# COMPUTE_CLUSTER0_A72SS0_CORE0_ECC_AGGR register map
Vendor: Texas Instruments
Peripheral module from a debugger description file (folder J7VCL).
Registers are 32-bit, access not given, reset 0x0 unless marked. A register's access mark holds for its fields unless they carry their own. Offsets are as the file gives them; lines under a group give offsets from that group; [hi:lo] are bit positions; {n}, {i} and the like mark numbered series; 'fields as' and 'values as' point back to an identical list; <NAME> marks a mode.

## COMPUTE_CLUSTER0_A72SS0_CORE0_ECC_AGGR
0x00 A72SS_CORE0_ECC_REV ro reset 0x66A0EA00 — IP revision register.
  [31:0] REV — TI internal data. Identifies revision of peripheral.
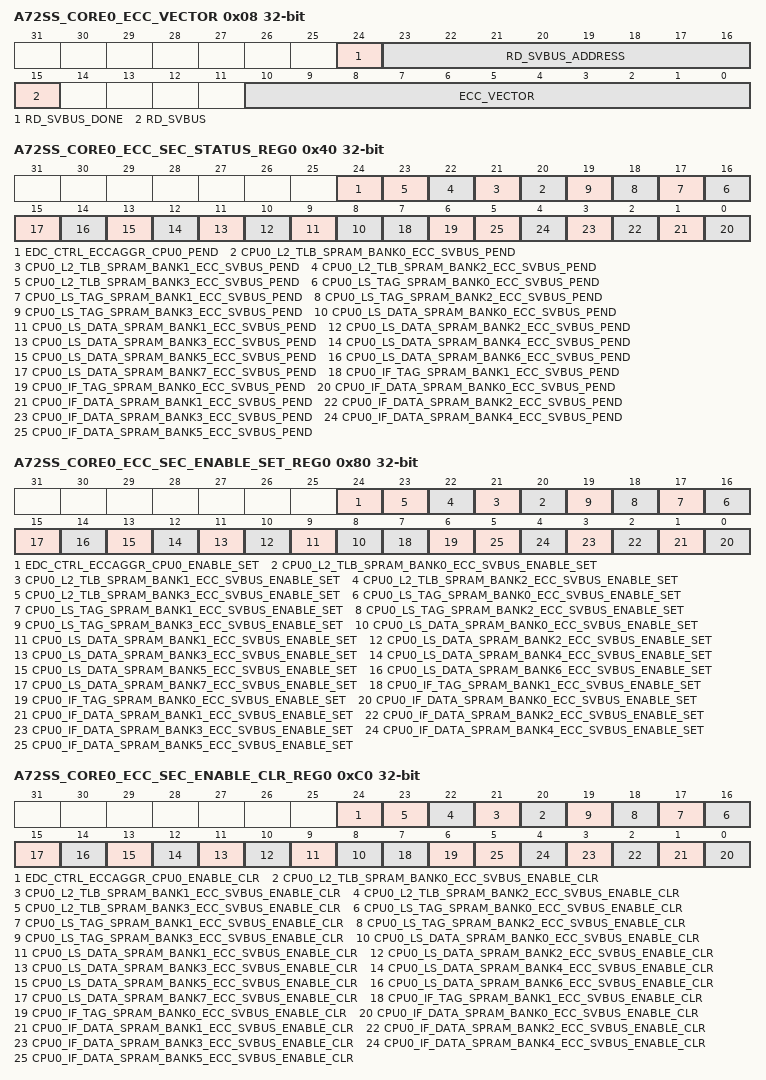
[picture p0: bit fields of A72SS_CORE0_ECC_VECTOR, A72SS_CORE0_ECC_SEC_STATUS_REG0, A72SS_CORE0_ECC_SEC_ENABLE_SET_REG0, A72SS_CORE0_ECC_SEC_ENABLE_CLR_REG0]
0x08 A72SS_CORE0_ECC_VECTOR — ECC vector register.
  [24] RD_SVBUS_DONE — Status to indicate if read on serial VBUS is complete, write of any value will clear this bit. (access RW1C)
  [23:16] RD_SVBUS_ADDRESS rw — Read address
  [15] RD_SVBUS — Write 1 to trigger a read on the serial VBUS (access RW1S)
  [10:0] ECC_VECTOR rw — Value written to select the corresponding ECC RAM for control or status
0x0C A72SS_CORE0_ECC_STAT ro reset 0x19 — Misc status register.
  [10:0] NUM_RAMS — Indicates the number of RAMs serviced by the ECC aggregator
0x3C A72SS_CORE0_ECC_SEC_EOI_REG — SEC EOI register. The EOI register is used to re-trigger the pulse interrupt signal to ensure that any nested interrupt events are serviced. The software interrupt handler must write to the EOI register at the end of the current interrupt processing routine, so that new events can re-trigger the pulse interrupt signal again. For level interrupt signals the EOI register is not functional and must not be used.
  [0] EOI_WR — EOI value (access RW1S)
0x40 A72SS_CORE0_ECC_SEC_STATUS_REG0 — SEC interrupt status register 0.
  [24] EDC_CTRL_ECCAGGR_CPU0_PEND — Interrupt pending status for edc_ctrl_eccaggr_cpu0_pend (access RW1S)
  [n+20] CPU0_L2_TLB_SPRAM_BANK{n}_ECC_SVBUS_PEND (n=0..3) — Interrupt pending status for cpu0_l2_tlb_spram_bank{n}_ecc_svbus_pend (access RW1S)
  [n+16] CPU0_LS_TAG_SPRAM_BANK{n}_ECC_SVBUS_PEND (n=0..3) — Interrupt pending status for cpu0_ls_tag_spram_bank{n}_ecc_svbus_pend (access RW1S)
  [n+8] CPU0_LS_DATA_SPRAM_BANK{n}_ECC_SVBUS_PEND (n=0..7) — Interrupt pending status for cpu0_ls_data_spram_bank{n}_ecc_svbus_pend (access RW1S)
  [7] CPU0_IF_TAG_SPRAM_BANK1_ECC_SVBUS_PEND — Interrupt pending status for cpu0_if_tag_spram_bank1_ecc_svbus_pend (access RW1S)
  [6] CPU0_IF_TAG_SPRAM_BANK0_ECC_SVBUS_PEND — Interrupt pending status for cpu0_if_tag_spram_bank0_ecc_svbus_pend (access RW1S)
  [n] CPU0_IF_DATA_SPRAM_BANK{n}_ECC_SVBUS_PEND (n=0..5) — Interrupt pending status for cpu0_if_data_spram_bank{n}_ecc_svbus_pend (access RW1S)
0x80 A72SS_CORE0_ECC_SEC_ENABLE_SET_REG0 — SEC interrupt enable set register 0.
  [24] EDC_CTRL_ECCAGGR_CPU0_ENABLE_SET — Interrupt enable set for edc_ctrl_eccaggr_cpu0_pend (access RW1S)
  [n+20] CPU0_L2_TLB_SPRAM_BANK{n}_ECC_SVBUS_ENABLE_SET (n=0..3) — Interrupt enable set for cpu0_l2_tlb_spram_bank{n}_ecc_svbus_pend (access RW1S)
  [n+16] CPU0_LS_TAG_SPRAM_BANK{n}_ECC_SVBUS_ENABLE_SET (n=0..3) — Interrupt enable set for cpu0_ls_tag_spram_bank{n}_ecc_svbus_pend (access RW1S)
  [n+8] CPU0_LS_DATA_SPRAM_BANK{n}_ECC_SVBUS_ENABLE_SET (n=0..7) — Interrupt enable set for cpu0_ls_data_spram_bank{n}_ecc_svbus_pend (access RW1S)
  [7] CPU0_IF_TAG_SPRAM_BANK1_ECC_SVBUS_ENABLE_SET — Interrupt enable set for cpu0_if_tag_spram_bank1_ecc_svbus_pend (access RW1S)
  [6] CPU0_IF_TAG_SPRAM_BANK0_ECC_SVBUS_ENABLE_SET — Interrupt enable set for cpu0_if_tag_spram_bank0_ecc_svbus_pend (access RW1S)
  [n] CPU0_IF_DATA_SPRAM_BANK{n}_ECC_SVBUS_ENABLE_SET (n=0..5) — Interrupt enable set for cpu0_if_data_spram_bank{n}_ecc_svbus_pend (access RW1S)
0xC0 A72SS_CORE0_ECC_SEC_ENABLE_CLR_REG0 — SEC interrupt enable clear register 0.
  [24] EDC_CTRL_ECCAGGR_CPU0_ENABLE_CLR — Interrupt enable clear for edc_ctrl_eccaggr_cpu0_pend (access RW1C)
  [n+20] CPU0_L2_TLB_SPRAM_BANK{n}_ECC_SVBUS_ENABLE_CLR (n=0..3) — Interrupt enable clear for cpu0_l2_tlb_spram_bank{n}_ecc_svbus_pend (access RW1C)
  [n+16] CPU0_LS_TAG_SPRAM_BANK{n}_ECC_SVBUS_ENABLE_CLR (n=0..3) — Interrupt enable clear for cpu0_ls_tag_spram_bank{n}_ecc_svbus_pend (access RW1C)
  [n+8] CPU0_LS_DATA_SPRAM_BANK{n}_ECC_SVBUS_ENABLE_CLR (n=0..7) — Interrupt enable clear for cpu0_ls_data_spram_bank{n}_ecc_svbus_pend (access RW1C)
  [7] CPU0_IF_TAG_SPRAM_BANK1_ECC_SVBUS_ENABLE_CLR — Interrupt enable clear for cpu0_if_tag_spram_bank1_ecc_svbus_pend (access RW1C)
  [6] CPU0_IF_TAG_SPRAM_BANK0_ECC_SVBUS_ENABLE_CLR — Interrupt enable clear for cpu0_if_tag_spram_bank0_ecc_svbus_pend (access RW1C)
  [n] CPU0_IF_DATA_SPRAM_BANK{n}_ECC_SVBUS_ENABLE_CLR (n=0..5) — Interrupt enable clear for cpu0_if_data_spram_bank{n}_ecc_svbus_pend (access RW1C)
0x13C A72SS_CORE0_ECC_DED_EOI_REG — DED EOI register. The EOI register is used to re-trigger the pulse interrupt signal to ensure that any nested interrupt events are serviced. The software interrupt handler must write to the EOI register at the end of the current interrupt processing routine, so that new events can re-trigger the pulse interrupt signal again. For level interrupt signals the EOI register is not functional and must not be used.
  [0] EOI_WR — EOI value (access RW1S)
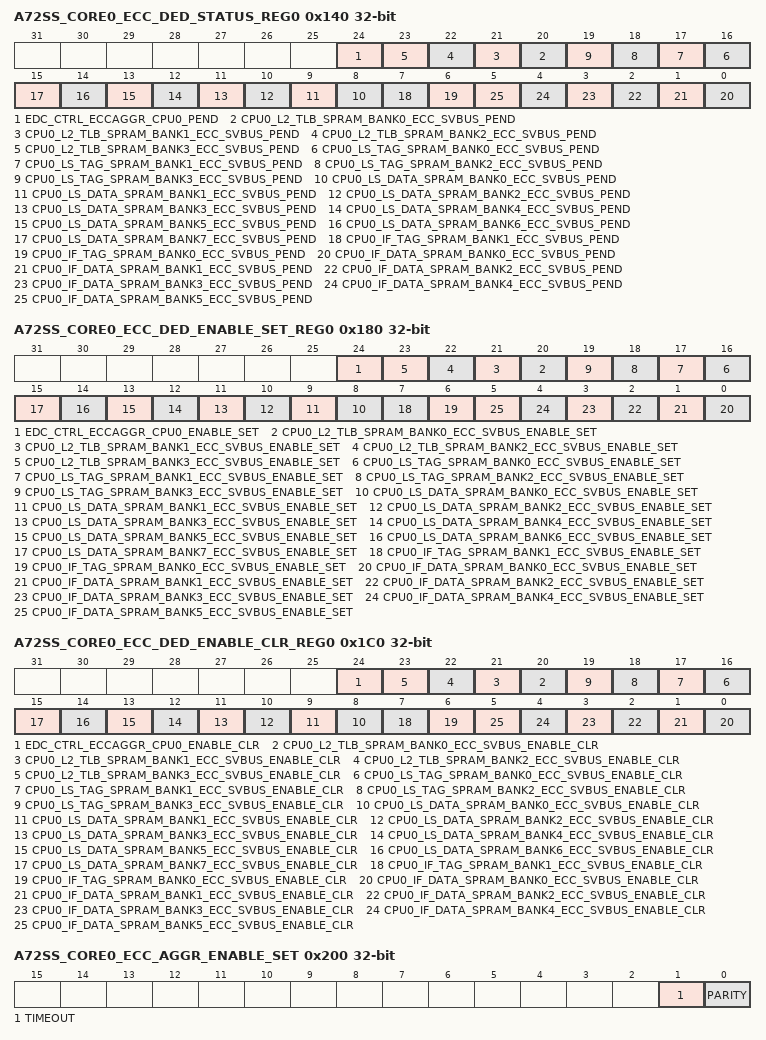
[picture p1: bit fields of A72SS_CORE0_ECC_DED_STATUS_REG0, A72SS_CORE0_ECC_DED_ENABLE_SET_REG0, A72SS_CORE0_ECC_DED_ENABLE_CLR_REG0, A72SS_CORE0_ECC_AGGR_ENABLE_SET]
0x140 A72SS_CORE0_ECC_DED_STATUS_REG0 — DED interrupt status register 0.
  fields as A72SS_CORE0_ECC_SEC_STATUS_REG0
0x180 A72SS_CORE0_ECC_DED_ENABLE_SET_REG0 — DED interrupt enable set register 0.
  fields as A72SS_CORE0_ECC_SEC_ENABLE_SET_REG0
0x1C0 A72SS_CORE0_ECC_DED_ENABLE_CLR_REG0 — DED interrupt enable clear register 0.
  fields as A72SS_CORE0_ECC_SEC_ENABLE_CLR_REG0
0x200 A72SS_CORE0_ECC_AGGR_ENABLE_SET — AGGR interrupt enable set register.
  [1] TIMEOUT — Interrupt enable set for svbus timeout errors (access RW1S)
  [0] PARITY — Interrupt enable set for parity errors (access RW1S)
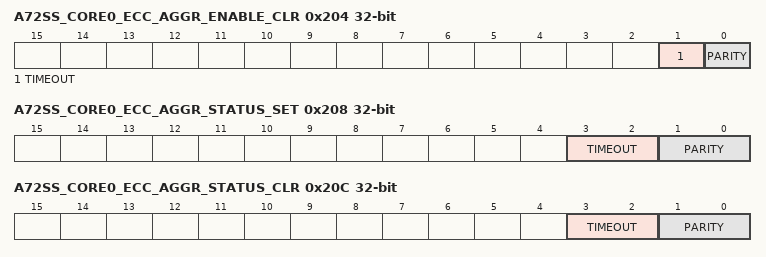
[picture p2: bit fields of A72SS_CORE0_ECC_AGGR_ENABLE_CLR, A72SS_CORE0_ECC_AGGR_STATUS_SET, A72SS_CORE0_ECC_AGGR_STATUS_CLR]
0x204 A72SS_CORE0_ECC_AGGR_ENABLE_CLR — AGGR interrupt enable clear register.
  [1] TIMEOUT — Interrupt enable clear for svbus timeout errors (access RW1C)
  [0] PARITY — Interrupt enable clear for parity errors (access RW1C)
0x208 A72SS_CORE0_ECC_AGGR_STATUS_SET — AGGR interrupt status set register.
  [3:2] TIMEOUT — Interrupt status set for svbus timeout errors (access RWincr)
  [1:0] PARITY — Interrupt status set for parity errors (access RWincr)
0x20C A72SS_CORE0_ECC_AGGR_STATUS_CLR — AGGR interrupt status clear register.
  [3:2] TIMEOUT — Interrupt status clear for svbus timeout errors (access RWdecr)
  [1:0] PARITY — Interrupt status clear for parity errors (access RWdecr)
